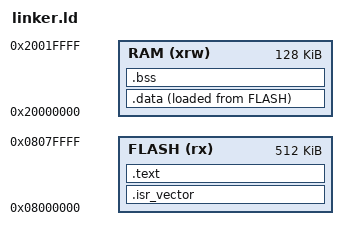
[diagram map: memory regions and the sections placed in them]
ENTRY(Reset_Handler)

MEMORY
{
  FLASH (rx) : ORIGIN = 0x08000000, LENGTH = 512K
  RAM (xrw)  : ORIGIN = 0x20000000, LENGTH = 128K
}

_estack = ORIGIN(RAM) + LENGTH(RAM);

SECTIONS
{
  .isr_vector : {
    KEEP(*(.isr_vector))
  } > FLASH

  .text : {
    *(.text*)
    *(.rodata*)
    . = ALIGN(4);
    _etext = .;
  } > FLASH

  _sidata = LOADADDR(.data);

  .data : {
    . = ALIGN(4);
    _sdata = .;
    *(.data*)
    . = ALIGN(4);
    _edata = .;
  } > RAM AT > FLASH

  .bss : {
    . = ALIGN(4);
    _sbss = .;
    __bss_start__ = .;  /* this is for rdimon(semihosting) for knowinf where zeroing starts */
    *(.bss*)
    *(COMMON)
    . = ALIGN(4);
    _ebss = .;
    __bss_end__ = .;    /*  this is for rdimon(semihosting) for knowinf where zeroing ends  */
    
    /* this is needed for fopen (Semihosting Heap Start). Now right after the  the end of zeroing the heap can start */
    end = .; 
    __end__ = .;
  } > RAM
}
